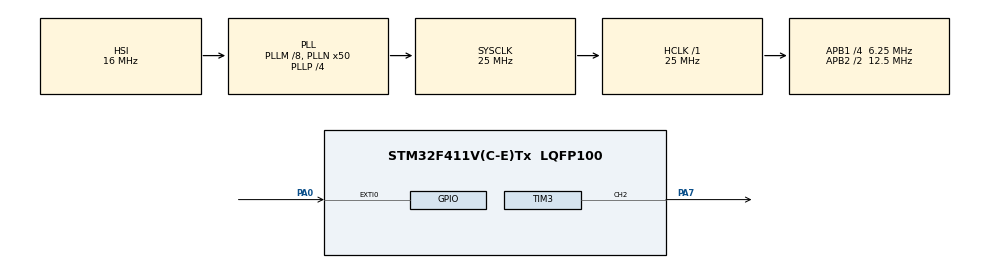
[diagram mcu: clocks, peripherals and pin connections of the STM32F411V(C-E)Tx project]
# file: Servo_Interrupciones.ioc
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Mcu.Family=STM32F4
Mcu.Name=STM32F411V(C-E)Tx
Mcu.Package=LQFP100
NVIC.EXTI0_IRQn=true\:0\:0\:false\:false\:true\:true\:true\:true
NVIC.PriorityGroup=NVIC_PRIORITYGROUP_0
NVIC.TIM3_IRQn=true\:0\:0\:false\:false\:true\:true\:true\:true
PA0-WKUP.Signal=GPXTI0
PA7.Signal=S_TIM3_CH2
ProjectManager.HeapSize=0x200
ProjectManager.StackSize=0x400
ProjectManager.TargetToolchain=STM32CubeIDE
RCC.48MHZClocksFreq_Value=12500000
RCC.AHBFreq_Value=25000000
RCC.APB1CLKDivider=RCC_HCLK_DIV4
RCC.APB1Freq_Value=6250000
RCC.APB1TimFreq_Value=12500000
RCC.APB2CLKDivider=RCC_HCLK_DIV2
RCC.APB2Freq_Value=12500000
RCC.APB2TimFreq_Value=25000000
RCC.CortexFreq_Value=25000000
RCC.HCLKFreq_Value=25000000
RCC.HSE_VALUE=8000000
RCC.HSI_VALUE=16000000
RCC.LSE_VALUE=32768
RCC.PLLI2SM=5
RCC.PLLI2SN=200
RCC.PLLM=8
RCC.PLLN=50
RCC.PLLP=RCC_PLLP_DIV4
RCC.PLLQ=8
RCC.SYSCLKFreq_VALUE=25000000
RCC.SYSCLKSource=RCC_SYSCLKSOURCE_PLLCLK
RCC.VCOOutputFreq_Value=100000000
SH.S_TIM3_CH2.0=TIM3_CH2,PWM Generation2 CH2
TIM3.Channel-PWM\ Generation2\ CH2=TIM_CHANNEL_2
TIM3.Period=999
TIM3.Prescaler=249
board=STM32F411E-DISCO

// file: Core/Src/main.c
/* USER CODE BEGIN Header */
/**
  ******************************************************************************
  * @file           : main.c
  * @brief          : Main program body
  ******************************************************************************
  * @attention
  *
  * Copyright (c) 2025 STMicroelectronics.
  * All rights reserved.
  *
  * This software is licensed under terms that can be found in the LICENSE file
  * in the root directory of this software component.
  * If no LICENSE file comes with this software, it is provided AS-IS.
  *
  ******************************************************************************
  */
/* USER CODE END Header */
#include "main.h"

TIM_HandleTypeDef htim3;

/* USER CODE BEGIN PV */
volatile uint8_t contador = 0;
uint8_t ISR = 0; //Flag
uint8_t state = 0; //estado (puerta abierta o puerta cerrada)
// debouncer
//uint8_t pulsacion = 1;
uint32_t tiempo = 0;
int8_t orden = 0;
int32_t counter = 0;
int8_t button_count = 0;
uint32_t lastTimeServoMove = 0;

/* USER CODE END PV */

void SystemClock_Config(void);
static void MX_GPIO_Init(void);
static void MX_TIM3_Init(void);

/* USER CODE BEGIN 0 */
void HAL_GPIO_EXTI_Callback(uint16_t GPIO_PIN)
{
	uint16_t angle; // en grados. se modifica esto
	uint32_t pulse; // mapeo

	/*if(state == 0){
		angle = 0;
		pulse = 40 + ((120 - 40) * angle) / 180; // mapeo
		__HAL_TIM_SET_COMPARE(&htim3, TIM_CHANNEL_2, pulse); // Configura el ciclo de trabajo a 1000 (Rojo apagado)
	} else{
		angle = 180;
		pulse = 40 + ((120 - 40) * angle) / 180; // mapeo
		__HAL_TIM_SET_COMPARE(&htim3, TIM_CHANNEL_2, pulse); // Configura el ciclo de trabajo a 1000 (Rojo apagado)
	}
	*/
	if(GPIO_PIN == GPIO_PIN_0 && ISR == 0){
		ISR = 1; // Se activa la bandera o flag
		lastTimeServoMove = HAL_GetTick(); // Se actualiza referencia
		if(state == 0){
			angle = 0;
			pulse = 40 + ((120 - 40) * angle) / 180; // mapeo
			__HAL_TIM_SET_COMPARE(&htim3, TIM_CHANNEL_2, pulse); // Configura el ciclo de trabajo a 1000 (Rojo apagado)
		} else{
			angle = 180;
			pulse = 40 + ((120 - 40) * angle) / 180; // mapeo
			__HAL_TIM_SET_COMPARE(&htim3, TIM_CHANNEL_2, pulse); // Configura el ciclo de trabajo a 1000 (Rojo apagado)
		}

		if(state==0){state=1;}
		else{state=0;}
	}

}

int debouncer(volatile int* button_int, GPIO_TypeDef* GPIO_port, uint16_t GPIO_number) {
    static uint8_t button_count = 0; // Contador para el número de pulsaciones confirmadas.
    static int counter = 0;          // Marca de tiempo para medir la duración entre pulsaciones.

    if (*button_int == 1) { // Verifica si el botón ha sido presionado.
        if (button_count == 0) { // Si es la primera pulsación registrada.
            counter = HAL_GetTick(); // Obtiene el tiempo actual (marca de tiempo).
            button_count++; // Incrementa el contador de pulsaciones.
        }
        if ((HAL_GetTick() - counter) >= 20) { // Comprueba si han pasado al menos 20 ms (para evitar rebotes).
            counter = HAL_GetTick(); // Actualiza el contador de tiempo.
            if (HAL_GPIO_ReadPin(GPIO_port, GPIO_number) != 1) {
                // Si el botón no está presionado después del intervalo, reinicia el contador.
                button_count = 1;
            } else {
                button_count++; // Si sigue presionado, incrementa el contador.
            }
            if (button_count == 4) { // Si el botón ha sido presionado 4 veces consecutivamente (sin rebotes).
                button_count = 0; // Reinicia el contador de pulsaciones.
                *button_int = 0;  // Resetea la variable de estado del botón.
                return 1;         // Devuelve 1 para indicar que la pulsación es válida.
            }
        }
    }
    return 0; // Si no se cumplen las condiciones, no hay pulsación válida.
}

/* USER CODE END 0 */

int main(void)
{

  /* MCU Configuration--------------------------------------------------------*/

  /* Reset of all peripherals, Initializes the Flash interface and the Systick. */
  HAL_Init();

  /* Configure the system clock */
  SystemClock_Config();

  /* Initialize all configured peripherals */
  MX_GPIO_Init();
  MX_TIM3_Init();
  /* USER CODE BEGIN 2 */
  HAL_TIM_PWM_Start(&htim3, TIM_CHANNEL_2);

  uint16_t angle = 180; // en grados. se modifica esto
  uint32_t pulse = 40 + ((120 - 40) * angle) / 180; // mapeo

  	__HAL_TIM_SET_COMPARE(&htim3, TIM_CHANNEL_2, pulse); // Configura el ciclo de trabajo a 1000 (Rojo apagado)

  	tiempo = HAL_GetTick();
  	counter = HAL_GetTick();

  /* USER CODE END 2 */

  /* Infinite loop */
  while (1)
  {

	  while (ISR == 0) {
	      contador++;
	  }
	  if (HAL_GetTick() - lastTimeServoMove >= 380) { // Esto impide invertir el sentido de giro cuando ya ha empezado a moverse el servo. 380ms es lo que tarda en pasar de mover de 0 a 180º
		  lastTimeServoMove = HAL_GetTick(); // Se actualiza referencia
		  ISR = 0;
	  }

	  contador = 0;
	  //ISR = 0;

  }
}

void SystemClock_Config(void)
{
  RCC_OscInitTypeDef RCC_OscInitStruct = {0};
  RCC_ClkInitTypeDef RCC_ClkInitStruct = {0};

  /** Configure the main internal regulator output voltage
  */
  __HAL_RCC_PWR_CLK_ENABLE();
  __HAL_PWR_VOLTAGESCALING_CONFIG(PWR_REGULATOR_VOLTAGE_SCALE1);

  /** Initializes the RCC Oscillators according to the specified parameters
  * in the RCC_OscInitTypeDef structure.
  */
  RCC_OscInitStruct.OscillatorType = RCC_OSCILLATORTYPE_HSI;
  RCC_OscInitStruct.HSIState = RCC_HSI_ON;
  RCC_OscInitStruct.HSICalibrationValue = RCC_HSICALIBRATION_DEFAULT;
  RCC_OscInitStruct.PLL.PLLState = RCC_PLL_ON;
  RCC_OscInitStruct.PLL.PLLSource = RCC_PLLSOURCE_HSI;
  RCC_OscInitStruct.PLL.PLLM = 8;
  RCC_OscInitStruct.PLL.PLLN = 50;
  RCC_OscInitStruct.PLL.PLLP = RCC_PLLP_DIV4;
  RCC_OscInitStruct.PLL.PLLQ = 8;
  if (HAL_RCC_OscConfig(&RCC_OscInitStruct) != HAL_OK)
  {
    Error_Handler();
  }

  /** Initializes the CPU, AHB and APB buses clocks
  */
  RCC_ClkInitStruct.ClockType = RCC_CLOCKTYPE_HCLK|RCC_CLOCKTYPE_SYSCLK
                              |RCC_CLOCKTYPE_PCLK1|RCC_CLOCKTYPE_PCLK2;
  RCC_ClkInitStruct.SYSCLKSource = RCC_SYSCLKSOURCE_PLLCLK;
  RCC_ClkInitStruct.AHBCLKDivider = RCC_SYSCLK_DIV1;
  RCC_ClkInitStruct.APB1CLKDivider = RCC_HCLK_DIV4;
  RCC_ClkInitStruct.APB2CLKDivider = RCC_HCLK_DIV2;

  if (HAL_RCC_ClockConfig(&RCC_ClkInitStruct, FLASH_LATENCY_0) != HAL_OK)
  {
    Error_Handler();
  }
}

static void MX_TIM3_Init(void)
{

  TIM_MasterConfigTypeDef sMasterConfig = {0};
  TIM_OC_InitTypeDef sConfigOC = {0};

  htim3.Instance = TIM3;
  htim3.Init.Prescaler = 249;
  htim3.Init.CounterMode = TIM_COUNTERMODE_UP;
  htim3.Init.Period = 999;
  htim3.Init.ClockDivision = TIM_CLOCKDIVISION_DIV1;
  htim3.Init.AutoReloadPreload = TIM_AUTORELOAD_PRELOAD_DISABLE;
  if (HAL_TIM_PWM_Init(&htim3) != HAL_OK)
  {
    Error_Handler();
  }
  sMasterConfig.MasterOutputTrigger = TIM_TRGO_RESET;
  sMasterConfig.MasterSlaveMode = TIM_MASTERSLAVEMODE_DISABLE;
  if (HAL_TIMEx_MasterConfigSynchronization(&htim3, &sMasterConfig) != HAL_OK)
  {
    Error_Handler();
  }
  sConfigOC.OCMode = TIM_OCMODE_PWM1;
  sConfigOC.Pulse = 0;
  sConfigOC.OCPolarity = TIM_OCPOLARITY_HIGH;
  sConfigOC.OCFastMode = TIM_OCFAST_DISABLE;
  if (HAL_TIM_PWM_ConfigChannel(&htim3, &sConfigOC, TIM_CHANNEL_2) != HAL_OK)
  {
    Error_Handler();
  }
  HAL_TIM_MspPostInit(&htim3);

}

static void MX_GPIO_Init(void)
{
  GPIO_InitTypeDef GPIO_InitStruct = {0};

  /* GPIO Ports Clock Enable */
  __HAL_RCC_GPIOA_CLK_ENABLE();

  /*Configure GPIO pin : PA0 */
  GPIO_InitStruct.Pin = GPIO_PIN_0;
  GPIO_InitStruct.Mode = GPIO_MODE_IT_RISING;
  GPIO_InitStruct.Pull = GPIO_NOPULL;
  HAL_GPIO_Init(GPIOA, &GPIO_InitStruct);

  /* EXTI interrupt init*/
  HAL_NVIC_SetPriority(EXTI0_IRQn, 0, 0);
  HAL_NVIC_EnableIRQ(EXTI0_IRQn);

}

void Error_Handler(void)
{
  __disable_irq();
  while (1)
  {
  }
}
